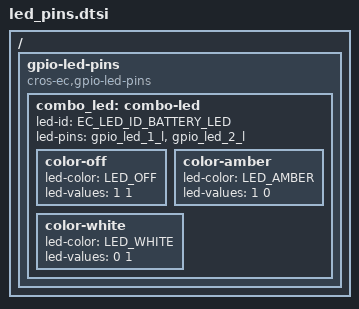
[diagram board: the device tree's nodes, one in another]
/* Copyright 2023 The ChromiumOS Authors
 * Use of this source code is governed by a BSD-style license that can be
 * found in the LICENSE file.
 */

/ {
	gpio-led-pins {
		compatible = "cros-ec,gpio-led-pins";

		combo_led: combo-led {
			led-id = "EC_LED_ID_BATTERY_LED";
			led-pins = <&gpio_led_1_l &gpio_led_2_l>;
			color-off {
				led-color = "LED_OFF";
				led-values = <1 1>;
			};

			color-amber {
				led-color = "LED_AMBER";
				led-values = <1 0>;
			};

			color-white {
				led-color = "LED_WHITE";
				led-values = <0 1>;
			};
		};
	};
};
